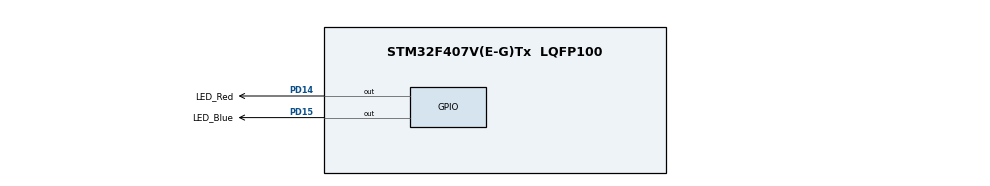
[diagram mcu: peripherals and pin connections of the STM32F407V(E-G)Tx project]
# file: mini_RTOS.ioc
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Mcu.Family=STM32F4
Mcu.Name=STM32F407V(E-G)Tx
Mcu.Package=LQFP100
NVIC.PriorityGroup=NVIC_PRIORITYGROUP_2
PD14.GPIO_Label=LED_Red
PD14.GPIO_Speed=GPIO_SPEED_FREQ_MEDIUM
PD14.Signal=GPIO_Output
PD15.GPIO_Label=LED_Blue
PD15.GPIO_Speed=GPIO_SPEED_FREQ_MEDIUM
PD15.Signal=GPIO_Output
PH0-OSC_IN.Mode=HSE-External-Oscillator
PH0-OSC_IN.Signal=RCC_OSC_IN
PH1-OSC_OUT.Mode=HSE-External-Oscillator
PH1-OSC_OUT.Signal=RCC_OSC_OUT
ProjectManager.HeapSize=0x080
ProjectManager.StackSize=0x400
ProjectManager.TargetToolchain=STM32CubeIDE
RCC.48MHZClocksFreq_Value=84000000
RCC.AHBFreq_Value=168000000
RCC.APB1CLKDivider=RCC_HCLK_DIV4
RCC.APB1Freq_Value=42000000
RCC.APB1TimFreq_Value=84000000
RCC.APB2CLKDivider=RCC_HCLK_DIV2
RCC.APB2Freq_Value=84000000
RCC.APB2TimFreq_Value=168000000
RCC.CortexFreq_Value=168000000
RCC.HCLKFreq_Value=168000000
RCC.HSE_VALUE=8000000
RCC.HSI_VALUE=16000000
RCC.LSE_VALUE=32768
RCC.PLLM=4
RCC.PLLN=168
RCC.PLLSourceVirtual=RCC_PLLSOURCE_HSE
RCC.SYSCLKFreq_VALUE=168000000
RCC.SYSCLKSource=RCC_SYSCLKSOURCE_PLLCLK
RCC.VCOOutputFreq_Value=336000000
board=custom

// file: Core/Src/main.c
/* USER CODE BEGIN Header */
/**
  ******************************************************************************
  * @file           : main.c
  * @brief          : Main program body
  ******************************************************************************
  * @attention
  *
  * Copyright (c) 2022 STMicroelectronics.
  * All rights reserved.
  *
  * This software is licensed under terms that can be found in the LICENSE file
  * in the root directory of this software component.
  * If no LICENSE file comes with this software, it is provided AS-IS.
  *
  ******************************************************************************
  */
/* USER CODE END Header */
#include "main.h"
#include "gpio.h"

/* USER CODE BEGIN Includes */

#include "utility.h"
#include "qpc.h"

/* USER CODE END Includes */

void SystemClock_Config(void);

/* USER CODE BEGIN 0 */

void red_blinky(QXThread * const me);
void blue_blinky(QXThread * const me);

uint32_t stackBlinkyRed[40] = {RESET};
QXThread LEDredThreadCtrl;
uint32_t stackBlinkyBlue[40] = {RESET};
QXThread LEDblueThreadCtrl;

/* USER CODE END 0 */

int main(void)
{

  /* MCU Configuration--------------------------------------------------------*/

  /* Reset of all peripherals, Initializes the Flash interface and the Systick. */
  LL_APB2_GRP1_EnableClock(LL_APB2_GRP1_PERIPH_SYSCFG);
  LL_APB1_GRP1_EnableClock(LL_APB1_GRP1_PERIPH_PWR);

  /* System interrupt init*/
  NVIC_SetPriorityGrouping(NVIC_PRIORITYGROUP_2);

  /* PendSV_IRQn interrupt configuration */
  NVIC_SetPriority(PendSV_IRQn, NVIC_EncodePriority(NVIC_GetPriorityGrouping(),3, 3));

  /* Configure the system clock */
  SystemClock_Config();

  /* Initialize all configured peripherals */
  MX_GPIO_Init();
  /* USER CODE BEGIN 2 */

  utility_init();

  QF_init();

  QXThread_ctor(&LEDredThreadCtrl, &red_blinky, RESET);
  QXTHREAD_START(&LEDredThreadCtrl,
		  	  	 5U,
		  	  	 (void *)0, 0,
				 stackBlinkyRed,
				 (sizeof(stackBlinkyRed) / sizeof(stackBlinkyRed[0])),
				 (void*)0);

  QXThread_ctor(&LEDblueThreadCtrl, &blue_blinky, RESET);
  QXTHREAD_START(&LEDblueThreadCtrl,
		  	  	 2U,
		  	  	 (void *)0, 0,
				 stackBlinkyBlue,
				 (sizeof(stackBlinkyBlue) / sizeof(stackBlinkyBlue[0])),
				 (void*)0);

  LL_SYSTICK_EnableIT();
  QF_run();

  /* USER CODE END 2 */

  /* Infinite loop */
  while (1)
  {

  }
}

void SystemClock_Config(void)
{
  LL_FLASH_SetLatency(LL_FLASH_LATENCY_5);
  while(LL_FLASH_GetLatency()!= LL_FLASH_LATENCY_5)
  {
  }
  LL_PWR_SetRegulVoltageScaling(LL_PWR_REGU_VOLTAGE_SCALE1);
  LL_RCC_HSE_Enable();

   /* Wait till HSE is ready */
  while(LL_RCC_HSE_IsReady() != 1)
  {

  }
  LL_RCC_PLL_ConfigDomain_SYS(LL_RCC_PLLSOURCE_HSE, LL_RCC_PLLM_DIV_4, 168, LL_RCC_PLLP_DIV_2);
  LL_RCC_PLL_Enable();

   /* Wait till PLL is ready */
  while(LL_RCC_PLL_IsReady() != 1)
  {

  }
  LL_RCC_SetAHBPrescaler(LL_RCC_SYSCLK_DIV_1);
  LL_RCC_SetAPB1Prescaler(LL_RCC_APB1_DIV_4);
  LL_RCC_SetAPB2Prescaler(LL_RCC_APB2_DIV_2);
  LL_RCC_SetSysClkSource(LL_RCC_SYS_CLKSOURCE_PLL);

   /* Wait till System clock is ready */
  while(LL_RCC_GetSysClkSource() != LL_RCC_SYS_CLKSOURCE_STATUS_PLL)
  {

  }
  LL_Init1msTick(168000000);
  LL_SetSystemCoreClock(168000000);
}

/* USER CODE BEGIN 4 */

void red_blinky(QXThread * const me)
{
	while(1)
	{
		LL_GPIO_TogglePin(LED_Red_GPIO_Port, LED_Red_Pin);
		QXThread_delay(500U);
	}
}

void blue_blinky(QXThread * const me)
{
	while(1)
	{
		LL_GPIO_TogglePin(LED_Blue_GPIO_Port, LED_Blue_Pin);
		QXThread_delay(1000U);
	}
}

void QF_onStartup(void)
{

}

void QXK_onIdle(void)
{

}

/* USER CODE END 4 */

void Error_Handler(void)
{
  __disable_irq();
  while (1)
  {
  }
}
